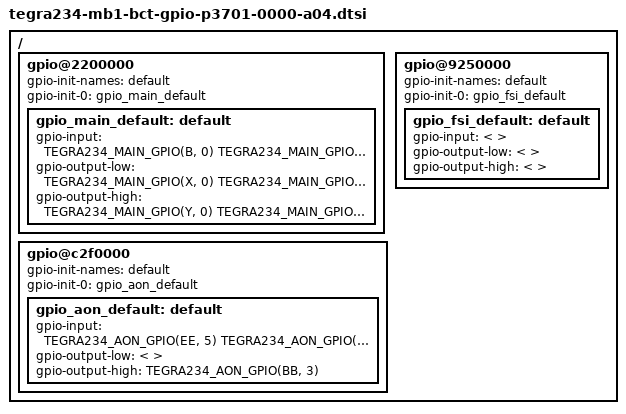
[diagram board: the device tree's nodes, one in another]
/*This dtsi file was generated by jetson_agx_orin.xlsm Revision: 2 */
/*
 * SPDX-FileCopyrightText: Copyright (c) 2022-2024 NVIDIA CORPORATION & AFFILIATES. All rights reserved.
 * SPDX-License-Identifier: BSD-3-Clause
 *
 * Redistribution and use in source and binary forms, with or without
 * modification, are permitted provided that the following conditions are met:
 *
 * 1. Redistributions of source code must retain the above copyright notice, this
 * list of conditions and the following disclaimer.
 *
 * 2. Redistributions in binary form must reproduce the above copyright notice,
 * this list of conditions and the following disclaimer in the documentation
 * and/or other materials provided with the distribution.
 *
 * 3. Neither the name of the copyright holder nor the names of its
 * contributors may be used to endorse or promote products derived from
 * this software without specific prior written permission.
 *
 * THIS SOFTWARE IS PROVIDED BY THE COPYRIGHT HOLDERS AND CONTRIBUTORS 'AS IS'
 * AND ANY EXPRESS OR IMPLIED WARRANTIES, INCLUDING, BUT NOT LIMITED TO, THE
 * IMPLIED WARRANTIES OF MERCHANTABILITY AND FITNESS FOR A PARTICULAR PURPOSE ARE
 * DISCLAIMED. IN NO EVENT SHALL THE COPYRIGHT HOLDER OR CONTRIBUTORS BE LIABLE
 * FOR ANY DIRECT, INDIRECT, INCIDENTAL, SPECIAL, EXEMPLARY, OR CONSEQUENTIAL
 * DAMAGES (INCLUDING, BUT NOT LIMITED TO, PROCUREMENT OF SUBSTITUTE GOODS OR
 * SERVICES; LOSS OF USE, DATA, OR PROFITS; OR BUSINESS INTERRUPTION) HOWEVER
 * CAUSED AND ON ANY THEORY OF LIABILITY, WHETHER IN CONTRACT, STRICT LIABILITY,
 * OR TORT (INCLUDING NEGLIGENCE OR OTHERWISE) ARISING IN ANY WAY OUT OF THE USE
 * OF THIS SOFTWARE, EVEN IF ADVISED OF THE POSSIBILITY OF SUCH DAMAGE.
 */

#include "tegra234-gpio.h"


/ {
	gpio@2200000 {
		gpio-init-names = "default";
		gpio-init-0 = <&gpio_main_default>;

		gpio_main_default: default {
			gpio-input = <
				TEGRA234_MAIN_GPIO(B, 0)
				TEGRA234_MAIN_GPIO(Y, 3)
				TEGRA234_MAIN_GPIO(Y, 4)
				TEGRA234_MAIN_GPIO(Z, 1)
				TEGRA234_MAIN_GPIO(Z, 2)
				TEGRA234_MAIN_GPIO(Z, 3)
				TEGRA234_MAIN_GPIO(Z, 4)
				TEGRA234_MAIN_GPIO(Z, 5)
				TEGRA234_MAIN_GPIO(Z, 6)
				TEGRA234_MAIN_GPIO(Z, 7)
				TEGRA234_MAIN_GPIO(P, 4)
				TEGRA234_MAIN_GPIO(P, 6)
				TEGRA234_MAIN_GPIO(Q, 6)
				TEGRA234_MAIN_GPIO(Q, 7)
				TEGRA234_MAIN_GPIO(R, 1)
				TEGRA234_MAIN_GPIO(N, 4)
				TEGRA234_MAIN_GPIO(N, 1)
				TEGRA234_MAIN_GPIO(G, 0)
				TEGRA234_MAIN_GPIO(G, 1)
				TEGRA234_MAIN_GPIO(G, 2)
				TEGRA234_MAIN_GPIO(G, 7)
				TEGRA234_MAIN_GPIO(H, 0)
				TEGRA234_MAIN_GPIO(H, 7)
				TEGRA234_MAIN_GPIO(I, 0)
				TEGRA234_MAIN_GPIO(I, 1)
				TEGRA234_MAIN_GPIO(I, 2)
				TEGRA234_MAIN_GPIO(AC, 3)
				TEGRA234_MAIN_GPIO(AC, 4)
				TEGRA234_MAIN_GPIO(AC, 5)
				TEGRA234_MAIN_GPIO(AE, 0)
				TEGRA234_MAIN_GPIO(AE, 1)
				TEGRA234_MAIN_GPIO(K, 0)
				TEGRA234_MAIN_GPIO(K, 1)
				TEGRA234_MAIN_GPIO(K, 6)
				TEGRA234_MAIN_GPIO(K, 7)
				TEGRA234_MAIN_GPIO(L, 2)
				TEGRA234_MAIN_GPIO(L, 3)
				TEGRA234_MAIN_GPIO(AG, 0)
				TEGRA234_MAIN_GPIO(AG, 1)
				TEGRA234_MAIN_GPIO(AG, 2)
				TEGRA234_MAIN_GPIO(AG, 3)
				TEGRA234_MAIN_GPIO(AG, 6)
				TEGRA234_MAIN_GPIO(AG, 7)
				TEGRA234_MAIN_GPIO(AF, 2)
				TEGRA234_MAIN_GPIO(AF, 3)
				>;
			gpio-output-low = <
				TEGRA234_MAIN_GPIO(X, 0)
				TEGRA234_MAIN_GPIO(X, 1)
				TEGRA234_MAIN_GPIO(Q, 4)
				TEGRA234_MAIN_GPIO(N, 3)
				TEGRA234_MAIN_GPIO(H, 1)
				TEGRA234_MAIN_GPIO(H, 3)
				TEGRA234_MAIN_GPIO(H, 4)
				TEGRA234_MAIN_GPIO(H, 5)
				TEGRA234_MAIN_GPIO(H, 6)
				TEGRA234_MAIN_GPIO(I, 5)
				TEGRA234_MAIN_GPIO(AC, 0)
				TEGRA234_MAIN_GPIO(AC, 1)
				TEGRA234_MAIN_GPIO(AC, 2)
				TEGRA234_MAIN_GPIO(A, 1)
				TEGRA234_MAIN_GPIO(A, 2)
				>;
			gpio-output-high = <
				TEGRA234_MAIN_GPIO(Y, 0)
				TEGRA234_MAIN_GPIO(Y, 1)
				TEGRA234_MAIN_GPIO(Y, 2)
				TEGRA234_MAIN_GPIO(Z, 0)
				TEGRA234_MAIN_GPIO(Q, 1)
				TEGRA234_MAIN_GPIO(G, 3)
				TEGRA234_MAIN_GPIO(AC, 7)
				TEGRA234_MAIN_GPIO(K, 5)
				TEGRA234_MAIN_GPIO(A, 0)
				TEGRA234_MAIN_GPIO(A, 3)
				>;
		};
	};
	gpio@c2f0000 {
		gpio-init-names = "default";
		gpio-init-0 = <&gpio_aon_default>;

		gpio_aon_default: default {
			gpio-input = <
				TEGRA234_AON_GPIO(EE, 5)
				TEGRA234_AON_GPIO(EE, 6)
				TEGRA234_AON_GPIO(EE, 2)
				TEGRA234_AON_GPIO(EE, 4)
				TEGRA234_AON_GPIO(CC, 0)
				TEGRA234_AON_GPIO(CC, 1)
				TEGRA234_AON_GPIO(CC, 2)
				TEGRA234_AON_GPIO(CC, 3)
				TEGRA234_AON_GPIO(AA, 0)
				TEGRA234_AON_GPIO(AA, 1)
				TEGRA234_AON_GPIO(AA, 2)
				TEGRA234_AON_GPIO(AA, 3)
				TEGRA234_AON_GPIO(BB, 0)
				TEGRA234_AON_GPIO(BB, 1)
				>;
			gpio-output-low = <
				>;
			gpio-output-high = <
				TEGRA234_AON_GPIO(BB, 3)
				>;
		};
	};
	gpio@9250000 {
		gpio-init-names = "default";
		gpio-init-0 = <&gpio_fsi_default>;

		gpio_fsi_default: default {
			gpio-input = <
				>;
			gpio-output-low = <
				>;
			gpio-output-high = <
				>;
		};
	};

};
